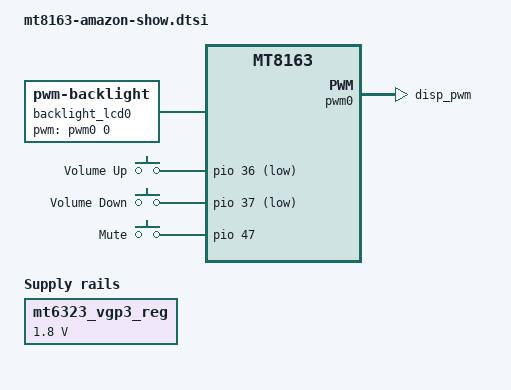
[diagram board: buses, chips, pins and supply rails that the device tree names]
// SPDX-License-Identifier: GPL-2.0-only OR MIT
/*
 * Copyright (c) 2025-2026 Ben Grisdale <bengris32@protonmail.ch>
 * Copyright (c) 2025-2026 Jack Matthews <jack@jackmatthe.ws>
 */

#include <dt-bindings/gpio/gpio.h>
#include <dt-bindings/input/input.h>

#include "mt8163-amazon-common.dtsi"

/ {
	backlight_lcd0: backlight {
		compatible = "pwm-backlight";
		pwms = <&pwm0 0 500000>;
		default-brightness-level = <128>;
	};

	gpio-keys {
		compatible = "gpio-keys";

		key-volume-up {
			label = "Volume Up";
			linux,code = <KEY_VOLUMEUP>;
			gpios = <&pio 36 GPIO_ACTIVE_LOW>;
		};

		key-volume-down {
			label = "Volume Down";
			linux,code = <KEY_VOLUMEDOWN>;
			gpios = <&pio 37 GPIO_ACTIVE_LOW>;
		};

		key-mute {
			label = "Mute";
			linux,code = <KEY_POWER>;
			gpios = <&pio 47 GPIO_ACTIVE_HIGH>;
		};
	};
};

&pio {
	backlight_pwm_pins: backlight-pwm-pins {
		mux {
			function = "disp";
			groups = "disp_pwm";
		};
	};
};

&pwm0 {
	pinctrl-names = "default";
	pinctrl-0 = <&backlight_pwm_pins>;
	status = "okay";
};

/* Display IOVCC */
&mt6323_vgp3_reg {
	regulator-min-microvolt = <1800000>;
	regulator-max-microvolt = <1800000>;
};
